# M030GAE register map
File version: 1.0
Registers are 32-bit, read-write, reset 0x0 unless marked. A register's access mark holds for its fields unless they carry their own. Offsets are from the block's base; [hi:lo] are bit positions; {n}, {i} and the like mark numbered series; 'fields as' and 'values as' point back to an identical list.

## ADC — ADC Register Map
Base 0x40043000
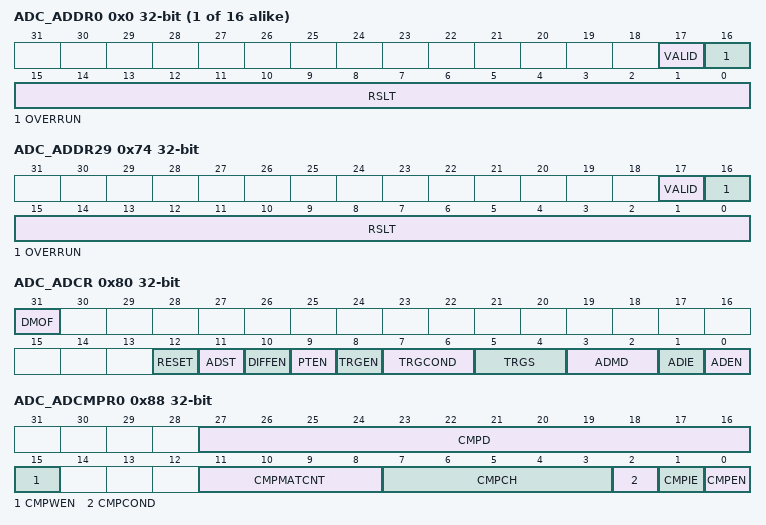
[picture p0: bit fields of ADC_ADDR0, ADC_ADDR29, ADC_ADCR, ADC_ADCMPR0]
{0x0+4i} ADC_ADDR{i} ro (i=0..15) — ADC Data Register {i}
  [17] VALID — Valid Flag (Read Only). This bit will be set to 1 when the conversion of the corresponding channel is completed. This bit will be cleared to 0 by hardware after ADDR register is read.
    0=Data in RSLT bits is not valid; 1=Data in RSLT bits is valid
  [16] OVERRUN — Overrun Flag (Read Only). If converted data in RSLT bits has not been read before new conversion result is loaded to this register, OVERRUN bit is set to 1. It is cleared by hardware after ADDR register is read.
    0=Data in RSLT bits is not overwritten; 1=Data in RSLT bits is overwritten
  [15:0] RSLT — A/D Conversion Result (Read Only). This field contains conversion result of ADC.
0x74 ADC_ADDR29 ro — ADC Data Register 29
  fields as ADC_ADDR0
0x80 ADC_ADCR — ADC Control Register
  [31] DMOF — Differential Input Mode Output Format. If user enables differential input mode, the conversion result can be expressed with binary straight format (unsigned format) or 2's complement format (signed format).
    0=A/D Conversion result will be filled in RSLT at ADDRx registers with unsigned format (straight binary format); 1=A/D Conversion result will be filled in RSLT at ADDRx registers with 2's complement format
  [12] RESET — ADC RESET (Write Protect). If user writes this bit, the ADC analog macro will reset. Calibration data in macro will be deleted, but registers in ADC controller will keep. Note: This bit is cleared by hardware.
  [11] ADST — A/D Conversion Start or Calibration Start. ADST bit can be set to 1 from four sources: software, external pin STADC, BPWM trigger and Timer trigger. ADST bit will be cleared to 0 by hardware automatically at the ends of Single mode, Single-cycle Scan mode and Calibration mode. In Continuous Scan mode and Burst mode, A/D conversion is continuously performed until software writes 0 to this bit or chip is reset.
    0=Conversion stops and A/D converter enters idle state; 1=Conversion starts or Calibration Start
  [10] DIFFEN — Differential Input Mode Control. Note: In Differential Input mode, only the even number of the two corresponding channels needs to be enabled in ADCHER register. The conversion result will be placed to the corresponding data register of the enabled channel.
    0=Single-end analog input mode; 1=Differential analog input mode
  [9] PTEN — PDMA Transfer Enable Bit. When A/D conversion is completed, the converted data is loaded into ADDR0~15, ADDR29. Software can enable this bit to generate a PDMA data transfer request.
    0=PDMA data transfer Disabled; 1=PDMA data transfer in ADDR0~15, ADDR29 Enabled
  [8] TRGEN — External Trigger Enable Bit. Enable or disable triggering of A/D conversion by external STADC pin, BPWM trigger and Timer trigger. If external trigger is enabled, the ADST bit can be set to 1 by the selected hardware trigger source. Note: The ADC external trigger function is only supported in Single-cycle Scan mode.
    0=External trigger Disabled; 1=External trigger Enabled
  [7:6] TRGCOND — External Trigger Condition. These two bits decide external pin STADC trigger event is level or edge. The signal must be kept at stable state at least 8 PCLKs for level trigger and at least 4 PCLKs for edge trigger.
    0=Low level; 1=High level; 2=Falling edge; 3=Rising edge
  [5:4] TRGS — Hardware Trigger Source. Note: Software should clear TRGEN bit and ADST bit to 0 before changing TRGS bits.
    0=A/D conversion is started by external STADC pin; 1=Timer0 ~ Timer1 overflow pulse trigger; 2=A/D conversion is started by BPWM trigger
  [3:2] ADMD — A/D Converter Operation Mode Control. Note 1: When changing the operation mode, software should clear ADST bit first. Note 2: In Burst mode, the A/D result data is always at ADC Data Register 0.
    0=Single conversion; 1=Burst conversion; 2=Single-cycle Scan; 3=Continuous Scan
  [1] ADIE — A/D Interrupt Enable Bit. A/D conversion end interrupt request is generated if ADIE bit is set to 1.
    0=A/D interrupt function Disabled; 1=A/D interrupt function Enabled
  [0] ADEN — A/D Converter Enable Bit. Note: Before starting A/D conversion function, this bit should be set to 1. Clear it to 0 to disable A/D converter analog circuit to save power consumption.
    0=A/D converter Disabled; 1=A/D converter Enabled
0x84 ADC_ADCHER — ADC Channel Enable Register
  [31:0] CHEN — Analog Input Channel Enable Control. Set ADCHER[15:0] bits to enable the corresponding analog input channel 15 ~ 0. If DIFFEN bit is set to 1, only the even number channel needs to be enabled. Besides, setting the ADCHER[29] bit will enable internal channel for band-gap voltage. Other bits are reserved. Note: If the internal channel for band-gap voltage (CHEN[29]) is active, the maximum sampling rate will be 300k SPS.
    0=Channel Disabled; 1=Channel Enabled
0x88 ADC_ADCMPR0 — ADC Compare Register 0
  [27:16] CMPD — Comparison Data. The 12-bit data is used to compare with conversion result of specified channel. Note: CMPD bits should be filled in unsigned format (straight binary format).
  [15] CMPWEN — Compare Window Mode Enable Bit. Note: This bit is only presented in ADCMPR0 register.
    0=Compare Window Mode Disabled; 1=Compare Window Mode Enabled
  [11:8] CMPMATCNT — Compare Match Count. When the specified A/D channel analog conversion result matches the compare condition defined by CMPCOND bit, the internal match counter will increase 1. When the internal counter reaches the value to (CMPMATCNT +1), the CMPFx bit will be set.
  [7:3] CMPCH — Compare Channel Selection
    {v}=Channel {v} conversion result is selected to be compared (v=0..15); 28=Floating detect channel conversion result is selected to be compared; 29=Band-gap voltage conversion result is selected to be compared
  [2] CMPCOND — Compare Condition. Note: When the internal counter reaches to (CMPMATCNT +1), the CMPFx bit will be set.
    0=Set the compare condition as that when a 12-bit A/D conversion result is less than the 12-bit CMPD bits, the internal match counter will increase one; 1=Set the compare condition as that when a 12-bit A/D conversion result is greater than or equal to the 12-bit CMPD bits, the internal match counter will increase one
  [1] CMPIE — Compare Interrupt Enable Bit. If the compare function is enabled and the compare condition matches the setting of CMPCOND and CMPMATCNT, CMPFx bit will be asserted, in the meanwhile, if CMPIE bit is set to 1, a compare interrupt request is generated.
    0=Compare function interrupt Disabled; 1=Compare function interrupt Enabled
  [0] CMPEN — Compare Enable Bit. Set this bit to 1 to enable ADC controller to compare CMPD (ADCMPRx[27:16]) with specified channel conversion result when converted data is loaded into ADDR register.
    0=Compare function Disabled; 1=Compare function Enabled
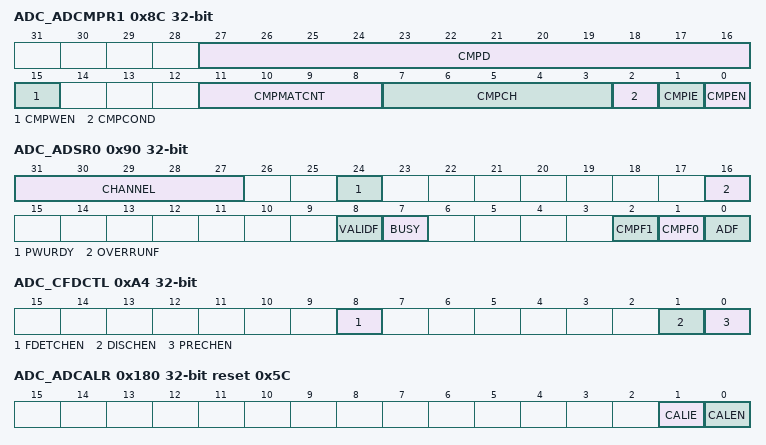
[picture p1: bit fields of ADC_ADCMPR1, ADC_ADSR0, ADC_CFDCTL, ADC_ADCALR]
0x8C ADC_ADCMPR1 — ADC Compare Register 1
  fields as ADC_ADCMPR0
0x90 ADC_ADSR0 — ADC Status Register0
  [31:27] CHANNEL ro — Current Conversion Channel (Read Only)
  [24] PWURDY ro — ADC Power-up Sequence Completed and Ready for Conversion (Read Only)
    0=ADC is not ready for conversion may be in power down state or in the progress of start up; 1=ADC is ready for conversion
  [16] OVERRUNF ro — Overrun Flag (Read Only). If any one of OVERRUN (ADDRx[16]) is set, this flag will be set to 1. Note: When ADC is in burst mode and the FIFO is overrun, this flag will be set to 1.
  [8] VALIDF ro — Data Valid Flag (Read Only). If any one of VALID (ADDRx[17]) is set, this flag will be set to 1. Note: When ADC is in burst mode and any conversion result is valid, this flag will be set to 1.
  [7] BUSY ro — BUSY/IDLE (Read Only). This bit is a mirror of ADST bit in ADCR register.
    0=A/D converter is in idle state; 1=A/D converter is busy at conversion
  [2] CMPF1 — Compare Flag 1. When the A/D conversion result of the selected channel meets setting condition in ADCMPR1 register, this bit is set to 1; it is cleared by writing 1 to it
    0=Conversion result in ADDR does not meet ADCMPR1 setting; 1=Conversion result in ADDR meets ADCMPR1 setting
  [1] CMPF0 — Compare Flag 0. When the A/D conversion result of the selected channel meets setting condition in ADCMPR0 register then this bit is set to 1. This bit is cleared by writing 1 to it.
    0=Conversion result in ADDR does not meet ADCMPR0 setting; 1=Conversion result in ADDR meets ADCMPR0 setting
  [0] ADF — A/D Conversion End Flag. A status flag that indicates the end of A/D conversion. Software can write 1 to clear this bit. The ADF bit is set to 1 at the following three conditions: When A/D conversion ends in Single mode. When A/D conversion ends on all specified channels in Single-cycle Scan mode and Continuous Scan mode. When more than or equal to 4 samples in FIFO in Burst mode.
0x94 ADC_ADSR1 ro — ADC Status Register1
  [31:0] VALID — Data Valid Flag (Read Only). VALID[29, 15:0] are the mirror of the VALID bits in ADDR29[17], ADDR15[17]~ ADDR0[17]. The other bits are reserved. Note: When ADC is in burst mode and any conversion result is valid, VALID[29, 15:0] will be set to 1.
0x98 ADC_ADSR2 ro — ADC Status Register2
  [31:0] OVERRUN — Overrun Flag (Read Only). OVERRUN[29, 15:0] are the mirror of the OVERRUN bit in ADDR29[16], ADDR15[16] ~ ADDR0[16]. The other bits are reserved. Note: When ADC is in burst mode and the FIFO is overrun, OVERRUN[29, 15:0] will be set to 1.
0xA0 ADC_ESMPCTL — ADC Extend Sample Time Control Register
  [7:0] EXTSMPT — ADC Sampling Time Extend. When ADC converting at high conversion rate, the sampling time of analog input voltage may not enough if input channel loading is heavy, user can extend ADC sampling time after trigger source is coming to get enough sampling time. The range of start delay time is from 0~255 ADC clock.
0xA4 ADC_CFDCTL — ADC Channel Floating Detect Control Register
  [8] FDETCHEN — Floating Detect Channel Enable Bit. Note: if FDETCHEN is enabled, internal channel is always turned on.
    0=Floating Detect Channel Disabled; 1=Floating Detect Channel Enabled
  [1] DISCHEN — Discharge Enable Bit. Note: Analog input voltage is 1/2 VREF when PRECHEN and DISCHEN are all enabled.
    0=Channel discharge Disabled; 1=Channel discharge Enabled
  [0] PRECHEN — Precharge Enable Bit. Note: Analog input voltage is 1/2 VREF when PRECHEN and DISCHEN are all enabled.
    0=Channel precharge Disabled; 1=Channel precharge Enabled
0x100 ADC_ADPDMA ro — ADC PDMA Current Transfer Data Register
  [17:0] CURDAT — ADC PDMA Current Transfer Data Register (Read Only). When PDMA transferring, read this register can monitor current PDMA transfer data. Current PDMA transfer data could be the content of ADDR0 ~ ADDR15, and ADDR29 registers.
0x180 ADC_ADCALR reset 0x5C — ADC Calibration Mode Register
  [1] CALIE — Calibration Interrupt Enable Bit. If calibration function is enabled and the calibration is finished, CALIF bit will be asserted, in the meanwhile, if CALIE bit is set to 1, a calibration interrupt request is generated.
    0=Calibration function Interrupt Disabled; 1=Calibration function Interrupt Enabled
  [0] CALEN — Calibration Function Enable Bit. Note: If chip is powered off, calibration function should be executed again.
    0=Calibration function Disabled
0x184 ADC_ADCALSTSR — ADC Calibration Status Register
  [0] CALIF — Calibration Finish Interrupt Flag. If calibration is finished, this flag will be set to 1. It is cleared by writing 1 to it.
